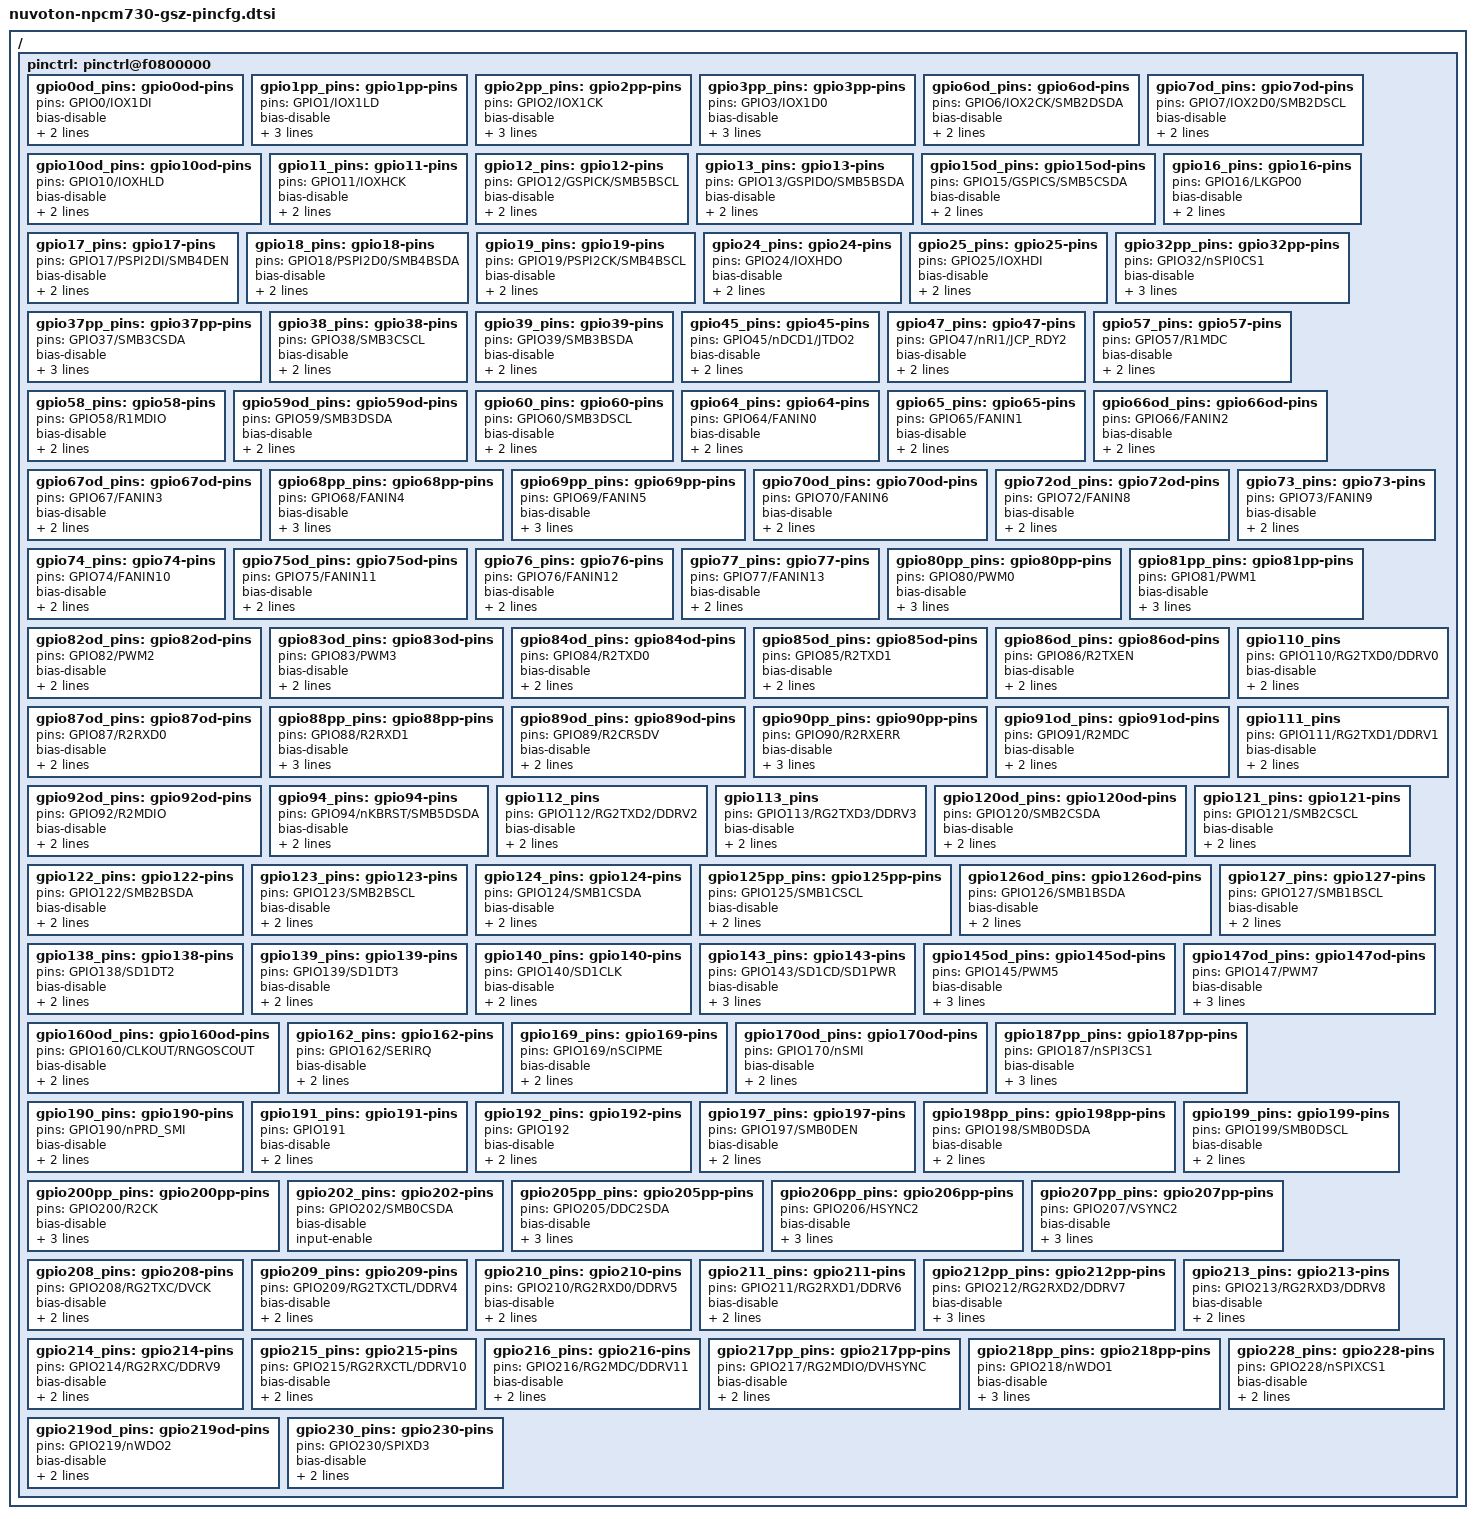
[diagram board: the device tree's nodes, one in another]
// SPDX-License-Identifier: GPL-2.0
// Copyright (c) 2018 Nuvoton Technology tomer.maimon@nuvoton.com
// Copyright (c) 2020 Quanta Computer Inc. Fran.Hsu@quantatw.com
// Copyright (c) 2020 Quanta Computer Inc. Duke.Du@quantatw.com

/ {
	pinctrl: pinctrl@f0800000 {
		gpio0od_pins: gpio0od-pins {
			pins = "GPIO0/IOX1DI";
			bias-disable;
			drive-open-drain;
			persist-enable;
		};
		gpio1pp_pins: gpio1pp-pins {
			pins = "GPIO1/IOX1LD";
			bias-disable;
			output-low;
			drive-push-pull;
			persist-enable;
		};
		gpio2pp_pins: gpio2pp-pins {
			pins = "GPIO2/IOX1CK";
			bias-disable;
			output-low;
			drive-push-pull;
			persist-enable;
		};
		gpio3pp_pins: gpio3pp-pins {
			pins = "GPIO3/IOX1D0";
			bias-disable;
			output-low;
			drive-push-pull;
			persist-enable;
		};
		gpio6od_pins: gpio6od-pins {
			pins = "GPIO6/IOX2CK/SMB2DSDA";
			bias-disable;
			drive-open-drain;
			persist-enable;
		};
		gpio7od_pins: gpio7od-pins {
			pins = "GPIO7/IOX2D0/SMB2DSCL";
			bias-disable;
			drive-open-drain;
			persist-enable;
		};
		gpio10od_pins: gpio10od-pins {
			pins = "GPIO10/IOXHLD";
			bias-disable;
			drive-open-drain;
			persist-enable;
		};
		gpio11_pins: gpio11-pins {
			pins = "GPIO11/IOXHCK";
			bias-disable;
			input-enable;
			event-clear;
		};
		gpio12_pins: gpio12-pins {
			pins = "GPIO12/GSPICK/SMB5BSCL";
			bias-disable;
			input-enable;
			event-clear;
		};
		gpio13_pins: gpio13-pins {
			pins = "GPIO13/GSPIDO/SMB5BSDA";
			bias-disable;
			input-enable;
			event-clear;
		};
		gpio15od_pins: gpio15od-pins {
			pins = "GPIO15/GSPICS/SMB5CSDA";
			bias-disable;
			drive-open-drain;
			persist-enable;
		};
		gpio16_pins: gpio16-pins {
			pins = "GPIO16/LKGPO0";
			bias-disable;
			input-enable;
			event-clear;
		};
		gpio17_pins: gpio17-pins {
			pins = "GPIO17/PSPI2DI/SMB4DEN";
			bias-disable;
			input-enable;
			event-clear;
		};
		gpio18_pins: gpio18-pins {
			pins = "GPIO18/PSPI2D0/SMB4BSDA";
			bias-disable;
			input-enable;
			event-clear;
		};
		gpio19_pins: gpio19-pins {
			pins = "GPIO19/PSPI2CK/SMB4BSCL";
			bias-disable;
			input-enable;
			event-clear;
		};
		gpio24_pins: gpio24-pins {
			pins = "GPIO24/IOXHDO";
			bias-disable;
			input-enable;
			event-clear;
		};
		gpio25_pins: gpio25-pins {
			pins = "GPIO25/IOXHDI";
			bias-disable;
			input-enable;
			event-clear;
		};
		gpio32pp_pins: gpio32pp-pins {
			pins = "GPIO32/nSPI0CS1";
			bias-disable;
			output-low;
			drive-push-pull;
			persist-enable;
		};
		gpio37pp_pins: gpio37pp-pins {
			pins = "GPIO37/SMB3CSDA";
			bias-disable;
			output-low;
			drive-push-pull;
			persist-enable;
		};
		gpio38_pins: gpio38-pins {
			pins = "GPIO38/SMB3CSCL";
			bias-disable;
			input-enable;
			event-clear;
		};
		gpio39_pins: gpio39-pins {
			pins = "GPIO39/SMB3BSDA";
			bias-disable;
			input-enable;
			event-clear;
		};
		gpio45_pins: gpio45-pins {
			pins = "GPIO45/nDCD1/JTDO2";
			bias-disable;
			input-enable;
			event-clear;
		};
		gpio47_pins: gpio47-pins {
			pins = "GPIO47/nRI1/JCP_RDY2";
			bias-disable;
			input-enable;
			event-clear;
		};
		gpio57_pins: gpio57-pins {
			pins = "GPIO57/R1MDC";
			bias-disable;
			input-enable;
			event-clear;
		};
		gpio58_pins: gpio58-pins {
			pins = "GPIO58/R1MDIO";
			bias-disable;
			input-enable;
			event-clear;
		};
		gpio59od_pins: gpio59od-pins {
			pins = "GPIO59/SMB3DSDA";
			bias-disable;
			drive-open-drain;
			persist-enable;
		};
		gpio60_pins: gpio60-pins {
			pins = "GPIO60/SMB3DSCL";
			bias-disable;
			input-enable;
			event-clear;
		};
		gpio64_pins: gpio64-pins {
			pins = "GPIO64/FANIN0";
			bias-disable;
			input-enable;
			event-clear;
		};
		gpio65_pins: gpio65-pins {
			pins = "GPIO65/FANIN1";
			bias-disable;
			input-enable;
			event-clear;
		};
		gpio66od_pins: gpio66od-pins {
			pins = "GPIO66/FANIN2";
			bias-disable;
			drive-open-drain;
			persist-enable;
		};
		gpio67od_pins: gpio67od-pins {
			pins = "GPIO67/FANIN3";
			bias-disable;
			drive-open-drain;
			persist-enable;
		};
		gpio68pp_pins: gpio68pp-pins {
			pins = "GPIO68/FANIN4";
			bias-disable;
			output-high;
			drive-push-pull;
			persist-enable;
		};
		gpio69pp_pins: gpio69pp-pins {
			pins = "GPIO69/FANIN5";
			bias-disable;
			output-low;
			drive-push-pull;
			persist-enable;
		};
		gpio70od_pins: gpio70od-pins {
			pins = "GPIO70/FANIN6";
			bias-disable;
			drive-open-drain;
			persist-enable;
		};
		gpio72od_pins: gpio72od-pins {
			pins = "GPIO72/FANIN8";
			bias-disable;
			drive-open-drain;
			persist-enable;
		};
		gpio73_pins: gpio73-pins {
			pins = "GPIO73/FANIN9";
			bias-disable;
			input-enable;
			event-clear;
		};
		gpio74_pins: gpio74-pins {
			pins = "GPIO74/FANIN10";
			bias-disable;
			input-enable;
			event-clear;
		};
		gpio75od_pins: gpio75od-pins {
			pins = "GPIO75/FANIN11";
			bias-disable;
			drive-open-drain;
			persist-enable;
		};
		gpio76_pins: gpio76-pins {
			pins = "GPIO76/FANIN12";
			bias-disable;
			input-enable;
			event-clear;
		};
		gpio77_pins: gpio77-pins {
			pins = "GPIO77/FANIN13";
			bias-disable;
			input-enable;
			event-clear;
		};
		gpio80pp_pins: gpio80pp-pins {
			pins = "GPIO80/PWM0";
			bias-disable;
			output-low;
			drive-push-pull;
			persist-enable;
		};
		gpio81pp_pins: gpio81pp-pins {
			pins = "GPIO81/PWM1";
			bias-disable;
			output-low;
			drive-push-pull;
			persist-enable;
		};
		gpio82od_pins: gpio82od-pins {
			pins = "GPIO82/PWM2";
			bias-disable;
			drive-open-drain;
			persist-enable;
		};
		gpio83od_pins: gpio83od-pins {
			pins = "GPIO83/PWM3";
			bias-disable;
			drive-open-drain;
			persist-enable;
		};
		gpio84od_pins: gpio84od-pins {
			pins = "GPIO84/R2TXD0";
			bias-disable;
			drive-open-drain;
			persist-enable;
		};
		gpio85od_pins: gpio85od-pins {
			pins = "GPIO85/R2TXD1";
			bias-disable;
			drive-open-drain;
			persist-enable;
		};
		gpio86od_pins: gpio86od-pins {
			pins = "GPIO86/R2TXEN";
			bias-disable;
			drive-open-drain;
			persist-enable;
		};
		gpio87od_pins: gpio87od-pins {
			pins = "GPIO87/R2RXD0";
			bias-disable;
			drive-open-drain;
			persist-enable;
		};
		gpio88pp_pins: gpio88pp-pins {
			pins = "GPIO88/R2RXD1";
			bias-disable;
			output-high;
			drive-push-pull;
			persist-enable;
		};
		gpio89od_pins: gpio89od-pins {
			pins = "GPIO89/R2CRSDV";
			bias-disable;
			drive-open-drain;
			persist-enable;
		};
		gpio90pp_pins: gpio90pp-pins {
			pins = "GPIO90/R2RXERR";
			bias-disable;
			output-high;
			drive-push-pull;
			persist-enable;
		};
		gpio91od_pins: gpio91od-pins {
			pins = "GPIO91/R2MDC";
			bias-disable;
			drive-open-drain;
			persist-enable;
		};
		gpio92od_pins: gpio92od-pins {
			pins = "GPIO92/R2MDIO";
			bias-disable;
			drive-open-drain;
			persist-enable;
		};
		gpio94_pins: gpio94-pins {
			pins = "GPIO94/nKBRST/SMB5DSDA";
			bias-disable;
			input-enable;
			event-clear;
		};
		gpio110_pins: gpio110_pins {
			pins = "GPIO110/RG2TXD0/DDRV0";
			bias-disable;
			input-enable;
			event-clear;
		};
		gpio111_pins: gpio111_pins {
			pins = "GPIO111/RG2TXD1/DDRV1";
			bias-disable;
			input-enable;
			event-clear;
		};
		gpio112_pins: gpio112_pins {
			pins = "GPIO112/RG2TXD2/DDRV2";
			bias-disable;
			input-enable;
			event-clear;
		};
		gpio113_pins: gpio113_pins {
			pins = "GPIO113/RG2TXD3/DDRV3";
			bias-disable;
			input-enable;
			event-clear;
		};
		gpio120od_pins: gpio120od-pins {
			pins = "GPIO120/SMB2CSDA";
			bias-disable;
			drive-open-drain;
			persist-enable;
		};
		gpio121_pins: gpio121-pins {
			pins = "GPIO121/SMB2CSCL";
			bias-disable;
			input-enable;
			event-clear;
		};
		gpio122_pins: gpio122-pins {
			pins = "GPIO122/SMB2BSDA";
			bias-disable;
			input-enable;
			event-clear;
		};
		gpio123_pins: gpio123-pins {
			pins = "GPIO123/SMB2BSCL";
			bias-disable;
			input-enable;
			event-clear;
		};
		gpio124_pins: gpio124-pins {
			pins = "GPIO124/SMB1CSDA";
			bias-disable;
			input-enable;
			event-clear;
		};
		gpio125pp_pins: gpio125pp-pins {
			pins = "GPIO125/SMB1CSCL";
			bias-disable;
			output-high;
			drive-push-pull;
		};
		gpio126od_pins: gpio126od-pins {
			pins = "GPIO126/SMB1BSDA";
			bias-disable;
			drive-open-drain;
			persist-enable;
		};
		gpio127_pins: gpio127-pins {
			pins = "GPIO127/SMB1BSCL";
			bias-disable;
			input-enable;
			event-clear;
		};
		gpio138_pins: gpio138-pins {
			pins = "GPIO138/SD1DT2";
			bias-disable;
			input-enable;
			event-clear;
		};
		gpio139_pins: gpio139-pins {
			pins = "GPIO139/SD1DT3";
			bias-disable;
			input-enable;
			event-clear;
		};
		gpio140_pins: gpio140-pins {
			pins = "GPIO140/SD1CLK";
			bias-disable;
			input-enable;
			event-clear;
		};
		gpio143_pins: gpio143-pins {
			pins = "GPIO143/SD1CD/SD1PWR";
			bias-disable;
			input-enable;
			event-clear;
			active-low;
		};
		gpio145od_pins: gpio145od-pins {
			pins = "GPIO145/PWM5";
			bias-disable;
			output-high;
			drive-open-drain;
			persist-enable;
		};
		gpio147od_pins: gpio147od-pins {
			pins = "GPIO147/PWM7";
			bias-disable;
			output-low;
			drive-open-drain;
			persist-enable;
		};
		gpio160od_pins: gpio160od-pins {
			pins = "GPIO160/CLKOUT/RNGOSCOUT";
			bias-disable;
			drive-open-drain;
			persist-enable;
		};
		gpio162_pins: gpio162-pins {
			pins = "GPIO162/SERIRQ";
			bias-disable;
			input-enable;
			event-clear;
		};
		gpio169_pins: gpio169-pins {
			pins = "GPIO169/nSCIPME";
			bias-disable;
			input-enable;
			event-clear;
		};
		gpio170od_pins: gpio170od-pins {
			pins = "GPIO170/nSMI";
			bias-disable;
			drive-open-drain;
			persist-enable;
		};
		gpio187pp_pins: gpio187pp-pins {
			pins = "GPIO187/nSPI3CS1";
			bias-disable;
			output-high;
			drive-push-pull;
			persist-enable;
		};
		gpio190_pins: gpio190-pins {
			pins = "GPIO190/nPRD_SMI";
			bias-disable;
			input-enable;
			event-clear;
		};
		gpio191_pins: gpio191-pins {
			pins = "GPIO191";
			bias-disable;
			input-enable;
			event-clear;
		};
		gpio192_pins: gpio192-pins {
			pins = "GPIO192";
			bias-disable;
			input-enable;
			event-clear;
		};
		gpio197_pins: gpio197-pins {
			pins = "GPIO197/SMB0DEN";
			bias-disable;
			input-enable;
			event-clear;
		};
		gpio198pp_pins: gpio198pp-pins {
			pins = "GPIO198/SMB0DSDA";
			bias-disable;
			output-low;
			drive-push-pull;
		};
		gpio199_pins: gpio199-pins {
			pins = "GPIO199/SMB0DSCL";
			bias-disable;
			input-enable;
			event-clear;
		};
		gpio200pp_pins: gpio200pp-pins { //MON_BMC_ALIVE_R
			pins = "GPIO200/R2CK";
			bias-disable;
			output-high;
			drive-push-pull;
			persist-enable;
		};
		gpio202_pins: gpio202-pins {
			pins = "GPIO202/SMB0CSDA";
			bias-disable;
			input-enable;
		};
		gpio205pp_pins: gpio205pp-pins {
			pins = "GPIO205/DDC2SDA";
			bias-disable;
			output-low;
			drive-push-pull;
			persist-enable;
		};
		gpio206pp_pins: gpio206pp-pins {
			pins = "GPIO206/HSYNC2";
			bias-disable;
			output-low;
			drive-push-pull;
			persist-enable;
		};
		gpio207pp_pins: gpio207pp-pins {
			pins = "GPIO207/VSYNC2";
			bias-disable;
			output-low;
			drive-push-pull;
			persist-enable;
		};
		gpio208_pins: gpio208-pins {
			pins = "GPIO208/RG2TXC/DVCK";
			bias-disable;
			input-enable;
			event-clear;
		};
		gpio209_pins: gpio209-pins {
			pins = "GPIO209/RG2TXCTL/DDRV4";
			bias-disable;
			input-enable;
			event-clear;
		};
		gpio210_pins: gpio210-pins {
			pins = "GPIO210/RG2RXD0/DDRV5";
			bias-disable;
			input-enable;
			event-clear;
		};
		gpio211_pins: gpio211-pins {
			pins = "GPIO211/RG2RXD1/DDRV6";
			bias-disable;
			input-enable;
			event-clear;
		};
		gpio212pp_pins: gpio212pp-pins {
			pins = "GPIO212/RG2RXD2/DDRV7";
			bias-disable;
			output-high;
			drive-push-pull;
			persist-enable;
		};
		gpio213_pins: gpio213-pins {
			pins = "GPIO213/RG2RXD3/DDRV8";
			bias-disable;
			input-enable;
			event-clear;
		};
		gpio214_pins: gpio214-pins {
			pins = "GPIO214/RG2RXC/DDRV9";
			bias-disable;
			input-enable;
			event-clear;
		};
		gpio215_pins: gpio215-pins {
			pins = "GPIO215/RG2RXCTL/DDRV10";
			bias-disable;
			input-enable;
			event-clear;
		};
		gpio216_pins: gpio216-pins {
			pins = "GPIO216/RG2MDC/DDRV11";
			bias-disable;
			input-enable;
			event-clear;
		};
		gpio217pp_pins: gpio217pp-pins { //BMC_FAULT_LED_R
			pins = "GPIO217/RG2MDIO/DVHSYNC";
			bias-disable;
			output-low;
			drive-push-pull;
		};
		gpio218pp_pins: gpio218pp-pins { //HOTSWAP_PWR_CYCLE_R
			pins = "GPIO218/nWDO1";
			bias-disable;
			output-low;
			drive-push-pull;
			persist-enable;
		};
		gpio219od_pins: gpio219od-pins {
			pins = "GPIO219/nWDO2";
			bias-disable;
			drive-open-drain;
			persist-enable;
		};
		gpio228_pins: gpio228-pins { //FM_CPU0_FIVR_FAULT_LVT3_PLD
			pins = "GPIO228/nSPIXCS1";
			bias-disable;
			input-enable;
			event-clear;
		};
		gpio230_pins: gpio230-pins { //FM_CPU1_FIVR_FAULT_LVT3_PLD
			pins = "GPIO230/SPIXD3";
			bias-disable;
			input-enable;
			event-clear;
		};
	};
};
